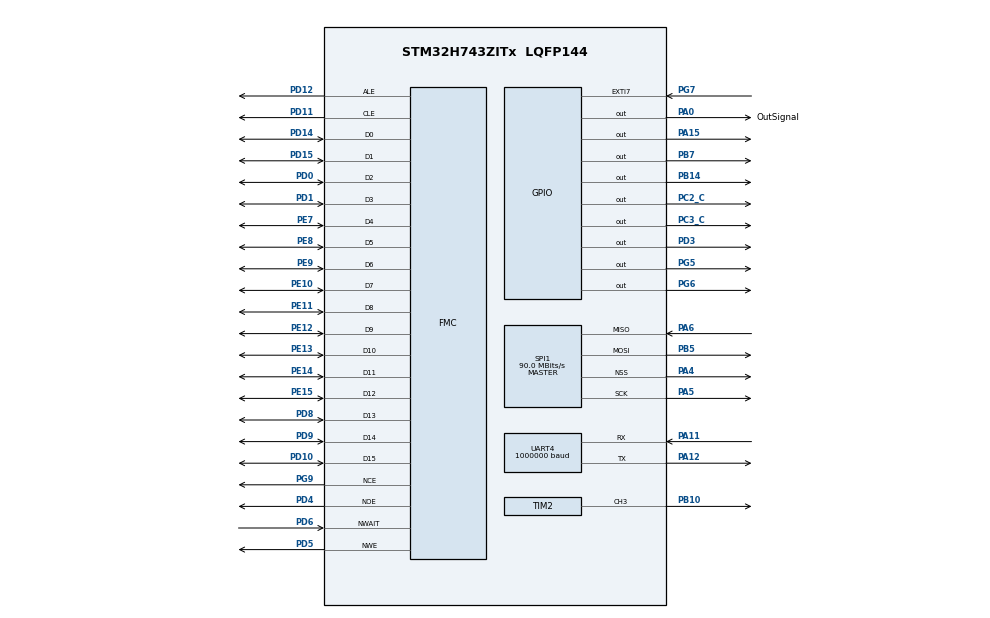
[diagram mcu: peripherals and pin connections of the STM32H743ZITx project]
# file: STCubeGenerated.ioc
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CORTEX_M7.AccessPermission-Cortex_Memory_Protection_Unit_Region0_Settings=MPU_REGION_FULL_ACCESS
CORTEX_M7.BaseAddress-Cortex_Memory_Protection_Unit_Region0_Settings=0x24060000
CORTEX_M7.CPU_DCache=Enabled
CORTEX_M7.CPU_ICache=Disabled
CORTEX_M7.Enable-Cortex_Memory_Protection_Unit_Region0_Settings=MPU_REGION_ENABLE
CORTEX_M7.IsBufferable-Cortex_Memory_Protection_Unit_Region0_Settings=MPU_ACCESS_BUFFERABLE
CORTEX_M7.IsShareable-Cortex_Memory_Protection_Unit_Region0_Settings=MPU_ACCESS_SHAREABLE
CORTEX_M7.MPU_Control=MPU_PRIVILEGED_DEFAULT
CORTEX_M7.Size-Cortex_Memory_Protection_Unit_Region0_Settings=MPU_REGION_SIZE_128KB
Dma.MEMTOMEM.0.Direction=DMA_MEMORY_TO_MEMORY
Dma.MEMTOMEM.0.EventEnable=DISABLE
Dma.MEMTOMEM.0.FIFOMode=DMA_FIFOMODE_ENABLE
Dma.MEMTOMEM.0.FIFOThreshold=DMA_FIFO_THRESHOLD_FULL
Dma.MEMTOMEM.0.Instance=DMA1_Stream0
Dma.MEMTOMEM.0.MemBurst=DMA_MBURST_SINGLE
Dma.MEMTOMEM.0.MemDataAlignment=DMA_MDATAALIGN_HALFWORD
Dma.MEMTOMEM.0.MemInc=DMA_MINC_ENABLE
Dma.MEMTOMEM.0.Mode=DMA_NORMAL
Dma.MEMTOMEM.0.PeriphBurst=DMA_PBURST_SINGLE
Dma.MEMTOMEM.0.PeriphDataAlignment=DMA_PDATAALIGN_HALFWORD
Dma.MEMTOMEM.0.PeriphInc=DMA_PINC_ENABLE
Dma.MEMTOMEM.0.Polarity=HAL_DMAMUX_REQ_GEN_RISING
Dma.MEMTOMEM.0.Priority=DMA_PRIORITY_VERY_HIGH
Dma.MEMTOMEM.0.RequestNumber=1
Dma.MEMTOMEM.0.SyncEnable=DISABLE
Dma.MEMTOMEM.0.SyncPolarity=HAL_DMAMUX_SYNC_NO_EVENT
Dma.MEMTOMEM.0.SyncRequestNumber=1
Dma.Request0=MEMTOMEM
Dma.Request1=UART4_RX
Dma.Request2=UART4_TX
Dma.Request3=SPI1_RX
Dma.Request4=SPI1_TX
Dma.SPI1_RX.3.Direction=DMA_PERIPH_TO_MEMORY
Dma.SPI1_RX.3.EventEnable=DISABLE
Dma.SPI1_RX.3.FIFOMode=DMA_FIFOMODE_ENABLE
Dma.SPI1_RX.3.FIFOThreshold=DMA_FIFO_THRESHOLD_HALFFULL
Dma.SPI1_RX.3.Instance=DMA1_Stream2
Dma.SPI1_RX.3.MemBurst=DMA_MBURST_SINGLE
Dma.SPI1_RX.3.MemDataAlignment=DMA_MDATAALIGN_HALFWORD
Dma.SPI1_RX.3.MemInc=DMA_MINC_ENABLE
Dma.SPI1_RX.3.Mode=DMA_NORMAL
Dma.SPI1_RX.3.PeriphBurst=DMA_PBURST_SINGLE
Dma.SPI1_RX.3.PeriphDataAlignment=DMA_PDATAALIGN_HALFWORD
Dma.SPI1_RX.3.PeriphInc=DMA_PINC_DISABLE
Dma.SPI1_RX.3.Polarity=HAL_DMAMUX_REQ_GEN_RISING
Dma.SPI1_RX.3.Priority=DMA_PRIORITY_MEDIUM
Dma.SPI1_RX.3.RequestNumber=1
Dma.SPI1_RX.3.SyncEnable=DISABLE
Dma.SPI1_RX.3.SyncPolarity=HAL_DMAMUX_SYNC_NO_EVENT
Dma.SPI1_RX.3.SyncRequestNumber=1
Dma.SPI1_TX.4.Direction=DMA_MEMORY_TO_PERIPH
Dma.SPI1_TX.4.EventEnable=DISABLE
Dma.SPI1_TX.4.FIFOMode=DMA_FIFOMODE_ENABLE
Dma.SPI1_TX.4.FIFOThreshold=DMA_FIFO_THRESHOLD_HALFFULL
Dma.SPI1_TX.4.Instance=DMA1_Stream3
Dma.SPI1_TX.4.MemBurst=DMA_MBURST_SINGLE
Dma.SPI1_TX.4.MemDataAlignment=DMA_MDATAALIGN_HALFWORD
Dma.SPI1_TX.4.MemInc=DMA_MINC_ENABLE
Dma.SPI1_TX.4.Mode=DMA_NORMAL
Dma.SPI1_TX.4.PeriphBurst=DMA_PBURST_SINGLE
Dma.SPI1_TX.4.PeriphDataAlignment=DMA_PDATAALIGN_HALFWORD
Dma.SPI1_TX.4.PeriphInc=DMA_PINC_DISABLE
Dma.SPI1_TX.4.Polarity=HAL_DMAMUX_REQ_GEN_RISING
Dma.SPI1_TX.4.Priority=DMA_PRIORITY_MEDIUM
Dma.SPI1_TX.4.RequestNumber=1
Dma.SPI1_TX.4.SyncEnable=DISABLE
Dma.SPI1_TX.4.SyncPolarity=HAL_DMAMUX_SYNC_NO_EVENT
Dma.SPI1_TX.4.SyncRequestNumber=1
Dma.UART4_RX.1.Direction=DMA_PERIPH_TO_MEMORY
Dma.UART4_RX.1.EventEnable=DISABLE
Dma.UART4_RX.1.FIFOMode=DMA_FIFOMODE_DISABLE
Dma.UART4_RX.1.Instance=DMA1_Stream5
Dma.UART4_RX.1.MemDataAlignment=DMA_MDATAALIGN_BYTE
Dma.UART4_RX.1.MemInc=DMA_MINC_ENABLE
Dma.UART4_RX.1.Mode=DMA_NORMAL
Dma.UART4_RX.1.PeriphDataAlignment=DMA_PDATAALIGN_BYTE
Dma.UART4_RX.1.PeriphInc=DMA_PINC_DISABLE
Dma.UART4_RX.1.Polarity=HAL_DMAMUX_REQ_GEN_RISING
Dma.UART4_RX.1.Priority=DMA_PRIORITY_MEDIUM
Dma.UART4_RX.1.RequestNumber=1
Dma.UART4_RX.1.SyncEnable=DISABLE
Dma.UART4_RX.1.SyncPolarity=HAL_DMAMUX_SYNC_NO_EVENT
Dma.UART4_RX.1.SyncRequestNumber=1
Dma.UART4_TX.2.Direction=DMA_MEMORY_TO_PERIPH
Dma.UART4_TX.2.EventEnable=DISABLE
Dma.UART4_TX.2.FIFOMode=DMA_FIFOMODE_DISABLE
Dma.UART4_TX.2.Instance=DMA1_Stream4
Dma.UART4_TX.2.MemDataAlignment=DMA_MDATAALIGN_BYTE
Dma.UART4_TX.2.MemInc=DMA_MINC_ENABLE
Dma.UART4_TX.2.Mode=DMA_NORMAL
Dma.UART4_TX.2.PeriphDataAlignment=DMA_PDATAALIGN_BYTE
Dma.UART4_TX.2.PeriphInc=DMA_PINC_DISABLE
Dma.UART4_TX.2.Polarity=HAL_DMAMUX_REQ_GEN_RISING
Dma.UART4_TX.2.Priority=DMA_PRIORITY_MEDIUM
Dma.UART4_TX.2.RequestNumber=1
Dma.UART4_TX.2.SyncEnable=DISABLE
Dma.UART4_TX.2.SyncPolarity=HAL_DMAMUX_SYNC_NO_EVENT
Dma.UART4_TX.2.SyncRequestNumber=1
FMC.CommonSpaceHiZSetupTime1=5
FMC.CommonSpaceHoldSetupTime1=5
FMC.CommonSpaceSetupTime1=5
FMC.CommonSpaceWaitSetupTime1=5
Mcu.Family=STM32H7
Mcu.Name=STM32H743ZITx
Mcu.Package=LQFP144
Mdma.MDMA_Channel0.Request0=SW
Mdma.MDMA_Channel0.RequestsNb=1
Mdma.MDMA_Channel0.SW.0.BlockCount=0
Mdma.MDMA_Channel0.SW.0.BlockDataLength=0
Mdma.MDMA_Channel0.SW.0.BufferTransferLength=16
Mdma.MDMA_Channel0.SW.0.CircularMode=MDMA_LINEAR_LIST
Mdma.MDMA_Channel0.SW.0.DataAlignment=MDMA_DATAALIGN_PACKENABLE
Mdma.MDMA_Channel0.SW.0.DestBlockAddressOffset=0
Mdma.MDMA_Channel0.SW.0.DestBurst=MDMA_DEST_BURST_SINGLE
Mdma.MDMA_Channel0.SW.0.DestDataSize=MDMA_DEST_DATASIZE_HALFWORD
Mdma.MDMA_Channel0.SW.0.DestinationInc=MDMA_DEST_INC_HALFWORD
Mdma.MDMA_Channel0.SW.0.DstAddress=0
Mdma.MDMA_Channel0.SW.0.Endianness=MDMA_LITTLE_ENDIANNESS_PRESERVE
Mdma.MDMA_Channel0.SW.0.Instance=MDMA_Channel0
Mdma.MDMA_Channel0.SW.0.MaskAddress=0
Mdma.MDMA_Channel0.SW.0.MaskData=0
Mdma.MDMA_Channel0.SW.0.Priority=MDMA_PRIORITY_VERY_HIGH
Mdma.MDMA_Channel0.SW.0.Rank=First
Mdma.MDMA_Channel0.SW.0.SourceBlockAddressOffset=-16
Mdma.MDMA_Channel0.SW.0.SourceBurst=MDMA_SOURCE_BURST_SINGLE
Mdma.MDMA_Channel0.SW.0.SourceDataSize=MDMA_SRC_DATASIZE_HALFWORD
Mdma.MDMA_Channel0.SW.0.SourceInc=MDMA_SRC_INC_HALFWORD
Mdma.MDMA_Channel0.SW.0.SrcAddress=0
Mdma.MDMA_Channel0.SW.0.TransferTriggerMode=MDMA_BLOCK_TRANSFER
Mdma.RequestSet0=MDMA_Channel0
Mdma.RequestSetsNb=1
NVIC.DMA1_Stream0_IRQn=true\:0\:0\:true\:false\:false\:true
NVIC.DMA1_Stream2_IRQn=true\:1\:0\:true\:false\:true\:false
NVIC.DMA1_Stream3_IRQn=true\:1\:0\:true\:false\:false\:false
NVIC.DMA1_Stream4_IRQn=true\:1\:0\:true\:false\:true\:false
NVIC.DMA1_Stream5_IRQn=true\:1\:0\:true\:false\:true\:true
NVIC.EXTI9_5_IRQn=true\:0\:0\:true\:false\:false\:true
NVIC.MDMA_IRQn=true\:0\:0\:false\:false\:false\:true
NVIC.PriorityGroup=NVIC_PRIORITYGROUP_4
NVIC.SPI1_IRQn=true\:1\:0\:true\:false\:true\:false
NVIC.TIM7_IRQn=true\:1\:0\:true\:false\:true\:false
NVIC.TimeBase=TIM7_IRQn
NVIC.TimeBaseIP=TIM7
NVIC.UART4_IRQn=true\:1\:0\:true\:false\:true\:true
PA0-WKUP.GPIO_Label=OutSignal
PA0-WKUP.GPIO_Speed=GPIO_SPEED_FREQ_VERY_HIGH
PA0-WKUP.Signal=GPIO_Output
PA11.GPIO_ModeDefaultPP=GPIO_MODE_AF_PP
PA11.GPIO_PuPd=GPIO_NOPULL
PA11.GPIO_Speed=GPIO_SPEED_FREQ_VERY_HIGH
PA11.Mode=Asynchronous
PA11.Signal=UART4_RX
PA12.GPIO_ModeDefaultPP=GPIO_MODE_AF_PP
PA12.GPIO_PuPd=GPIO_NOPULL
PA12.GPIO_Speed=GPIO_SPEED_FREQ_VERY_HIGH
PA12.Mode=Asynchronous
PA12.Signal=UART4_TX
PA13.Mode=Trace_Asynchronous_SW
PA13.Signal=SYS_JTMS-SWDIO
PA14.Mode=Trace_Asynchronous_SW
PA14.Signal=SYS_JTCK-SWCLK
PA15.GPIO_ModeDefaultOutputPP=GPIO_MODE_OUTPUT_PP
PA15.GPIO_PuPd=GPIO_NOPULL
PA15.GPIO_Speed=GPIO_SPEED_FREQ_LOW
PA15.PinState=GPIO_PIN_RESET
PA15.Signal=GPIO_Output
PA4.GPIO_PuPd=GPIO_PULLUP
PA4.GPIO_Speed=GPIO_SPEED_FREQ_VERY_HIGH
PA4.Mode=NSS_Signal_Hard_Output
PA4.Signal=SPI1_NSS
PA5.GPIO_Speed=GPIO_SPEED_FREQ_VERY_HIGH
PA5.Mode=Full_Duplex_Master
PA5.Signal=SPI1_SCK
PA6.GPIO_Speed=GPIO_SPEED_FREQ_VERY_HIGH
PA6.Mode=Full_Duplex_Master
PA6.Signal=SPI1_MISO
PB10.Signal=S_TIM2_CH3
PB14.GPIO_ModeDefaultOutputPP=GPIO_MODE_OUTPUT_PP
PB14.GPIO_PuPd=GPIO_NOPULL
PB14.GPIO_Speed=GPIO_SPEED_FREQ_LOW
PB14.PinState=GPIO_PIN_RESET
PB14.Signal=GPIO_Output
PB3.Mode=Trace_Asynchronous_SW
PB3.Signal=SYS_JTDO-SWO
PB5.GPIO_Speed=GPIO_SPEED_FREQ_VERY_HIGH
PB5.Mode=Full_Duplex_Master
PB5.Signal=SPI1_MOSI
PB7.GPIO_FM7=__NULL
PB7.GPIO_ModeDefaultOutputPP=GPIO_MODE_OUTPUT_PP
PB7.GPIO_PuPd=GPIO_NOPULL
PB7.GPIO_Speed=GPIO_SPEED_FREQ_LOW
PB7.PinState=GPIO_PIN_RESET
PB7.Signal=GPIO_Output
PC2_C.GPIO_ModeDefaultOutputPP=GPIO_MODE_OUTPUT_PP
PC2_C.GPIO_PuPd=GPIO_NOPULL
PC2_C.GPIO_Speed=GPIO_SPEED_FREQ_LOW
PC2_C.PinState=GPIO_PIN_RESET
PC2_C.Signal=GPIO_Output
PC3_C.GPIO_ModeDefaultOutputPP=GPIO_MODE_OUTPUT_PP
PC3_C.GPIO_PuPd=GPIO_NOPULL
PC3_C.GPIO_Speed=GPIO_SPEED_FREQ_LOW
PC3_C.PinState=GPIO_PIN_RESET
PC3_C.Signal=GPIO_Output
PD0.Signal=FMC_D2_DA2
PD1.Signal=FMC_D3_DA3
PD10.Signal=FMC_D15_DA15
PD11.Signal=FMC_A16_CLE
PD12.Signal=FMC_A17_ALE
PD14.Signal=FMC_D0_DA0
PD15.Signal=FMC_D1_DA1
PD3.GPIO_ModeDefaultOutputPP=GPIO_MODE_OUTPUT_PP
PD3.GPIO_PuPd=GPIO_NOPULL
PD3.GPIO_Speed=GPIO_SPEED_FREQ_LOW
PD3.PinState=GPIO_PIN_RESET
PD3.Signal=GPIO_Output
PD4.Signal=FMC_NOE
PD5.Signal=FMC_NWE
PD6.Signal=FMC_NWAIT
PD8.Signal=FMC_D13_DA13
PD9.Signal=FMC_D14_DA14
PE10.Signal=FMC_D7_DA7
PE11.Signal=FMC_D8_DA8
PE12.Signal=FMC_D9_DA9
PE13.Signal=FMC_D10_DA10
PE14.Signal=FMC_D11_DA11
PE15.Signal=FMC_D12_DA12
PE7.Signal=FMC_D4_DA4
PE8.Signal=FMC_D5_DA5
PE9.Signal=FMC_D6_DA6
PG5.GPIO_PuPd=GPIO_PULLUP
PG5.GPIO_Speed=GPIO_SPEED_FREQ_VERY_HIGH
PG5.Signal=GPIO_Output
PG6.GPIO_ModeDefaultOutputPP=GPIO_MODE_OUTPUT_PP
PG6.GPIO_PuPd=GPIO_PULLDOWN
PG6.GPIO_Speed=GPIO_SPEED_FREQ_VERY_HIGH
PG6.Signal=GPIO_Output
PG7.GPIO_ModeDefaultEXTI=GPIO_MODE_IT_RISING
PG7.GPIO_PuPd=GPIO_NOPULL
PG7.Signal=GPXTI7
PG9.Mode=NandChipSelect3_1
PG9.Signal=FMC_NCE
PH0-OSC_IN.Mode=HSE-External-Clock-Source
PH0-OSC_IN.Signal=RCC_OSC_IN
PH1-OSC_OUT.Mode=HSE-External-Clock-Source
PH1-OSC_OUT.Signal=RCC_OSC_OUT
ProjectManager.HeapSize=0x200
ProjectManager.StackSize=0x400
ProjectManager.TargetToolchain=Makefile
RCC.ADCFreq_Value=360000000
RCC.APB1Freq_Value=97500000
RCC.APB2Freq_Value=97500000
RCC.APB3Freq_Value=97500000
RCC.APB4Freq_Value=97500000
RCC.CortexFreq_Value=390000000
RCC.D1PPRE=RCC_APB3_DIV2
RCC.D2PPRE1=RCC_APB1_DIV2
RCC.D2PPRE2=RCC_APB2_DIV2
RCC.D3PPRE=RCC_APB4_DIV2
RCC.DIVM1=2
RCC.DIVM2=2
RCC.DIVN1=195
RCC.DIVN2=180
RCC.HCLKFreq_Value=195000000
RCC.HPRE=RCC_HCLK_DIV2
RCC.HSE_VALUE=8000000
RCC.PLLSourceVirtual=RCC_PLLSOURCE_HSE
RCC.SPI123CLockSelection=RCC_SPI123CLKSOURCE_PLL2
RCC.SYSCLKFreq_VALUE=390000000
RCC.SYSCLKSource=RCC_SYSCLKSOURCE_PLLCLK
RCC.USBFreq_Value=390000000
SH.FMC_A16_CLE.0=FMC_CLE,16b-dmux1
SH.FMC_A17_ALE.0=FMC_ALE,16b-dmux1
SH.FMC_D0_DA0.0=FMC_D0,16b-dmux1
SH.FMC_D10_DA10.0=FMC_D10,16b-dmux1
SH.FMC_D11_DA11.0=FMC_D11,16b-dmux1
SH.FMC_D12_DA12.0=FMC_D12,16b-dmux1
SH.FMC_D13_DA13.0=FMC_D13,16b-dmux1
SH.FMC_D14_DA14.0=FMC_D14,16b-dmux1
SH.FMC_D15_DA15.0=FMC_D15,16b-dmux1
SH.FMC_D1_DA1.0=FMC_D1,16b-dmux1
SH.FMC_D2_DA2.0=FMC_D2,16b-dmux1
SH.FMC_D3_DA3.0=FMC_D3,16b-dmux1
SH.FMC_D4_DA4.0=FMC_D4,16b-dmux1
SH.FMC_D5_DA5.0=FMC_D5,16b-dmux1
SH.FMC_D6_DA6.0=FMC_D6,16b-dmux1
SH.FMC_D7_DA7.0=FMC_D7,16b-dmux1
SH.FMC_D8_DA8.0=FMC_D8,16b-dmux1
SH.FMC_D9_DA9.0=FMC_D9,16b-dmux1
SH.FMC_NOE.0=FMC_NOE,16b-dmux1
SH.FMC_NWAIT.0=FMC_NWAIT,Wait1
SH.FMC_NWE.0=FMC_NWE,16b-dmux1
SH.S_TIM2_CH3.0=TIM2_CH3,PWM Generation3 CH3
SPI1.BaudRatePrescaler=SPI_BAUDRATEPRESCALER_4
SPI1.CalculateBaudRate=90.0 MBits/s
SPI1.DataSize=SPI_DATASIZE_16BIT
SPI1.Direction=SPI_DIRECTION_2LINES
SPI1.Mode=SPI_MODE_MASTER
SPI1.VirtualNSS=VM_NSSHARD
SPI1.VirtualType=VM_MASTER
TIM2.Channel-PWM\ Generation3\ CH3=TIM_CHANNEL_3
TIM2.Period=1079
TIM2.Pulse-PWM\ Generation3\ CH3=100
UART4.BaudRate=1000000
UART4.FIFOMode=FIFOMODE_ENABLE
UART4.WordLength=WORDLENGTH_8B
VP_SYS_VS_tim7.Mode=TIM7
board=STCubeGenerated

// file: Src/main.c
/**
  ******************************************************************************
  * @file           : main.c
  * @brief          : Main program body
  ******************************************************************************
  ** This notice applies to any and all portions of this file
  * that are not between comment pairs USER CODE BEGIN and
  * USER CODE END. Other portions of this file, whether
  * inserted by the user or by software development tools
  * are owned by their respective copyright owners.
  *
  * COPYRIGHT(c) 2018 STMicroelectronics
  *
  * Redistribution and use in source and binary forms, with or without modification,
  * are permitted provided that the following conditions are met:
  *   1. Redistributions of source code must retain the above copyright notice,
  *      this list of conditions and the following disclaimer.
  *   2. Redistributions in binary form must reproduce the above copyright notice,
  *      this list of conditions and the following disclaimer in the documentation
  *      and/or other materials provided with the distribution.
  *   3. Neither the name of STMicroelectronics nor the names of its contributors
  *      may be used to endorse or promote products derived from this software
  *      without specific prior written permission.
  *
  * THIS SOFTWARE IS PROVIDED BY THE COPYRIGHT HOLDERS AND CONTRIBUTORS "AS IS"
  * AND ANY EXPRESS OR IMPLIED WARRANTIES, INCLUDING, BUT NOT LIMITED TO, THE
  * IMPLIED WARRANTIES OF MERCHANTABILITY AND FITNESS FOR A PARTICULAR PURPOSE ARE
  * DISCLAIMED. IN NO EVENT SHALL THE COPYRIGHT HOLDER OR CONTRIBUTORS BE LIABLE
  * FOR ANY DIRECT, INDIRECT, INCIDENTAL, SPECIAL, EXEMPLARY, OR CONSEQUENTIAL
  * DAMAGES (INCLUDING, BUT NOT LIMITED TO, PROCUREMENT OF SUBSTITUTE GOODS OR
  * SERVICES; LOSS OF USE, DATA, OR PROFITS; OR BUSINESS INTERRUPTION) HOWEVER
  * CAUSED AND ON ANY THEORY OF LIABILITY, WHETHER IN CONTRACT, STRICT LIABILITY,
  * OR TORT (INCLUDING NEGLIGENCE OR OTHERWISE) ARISING IN ANY WAY OUT OF THE USE
  * OF THIS SOFTWARE, EVEN IF ADVISED OF THE POSSIBILITY OF SUCH DAMAGE.
  *
  ******************************************************************************
  */
#include "main.h"
#include "stm32h7xx_hal.h"

/* USER CODE BEGIN Includes */
#include "cmsis_os2.h"                  // ::CMSIS:RTOS2
/* USER CODE END Includes */

SPI_HandleTypeDef hspi1;
DMA_HandleTypeDef hdma_spi1_rx;
DMA_HandleTypeDef hdma_spi1_tx;

TIM_HandleTypeDef htim2;

UART_HandleTypeDef huart4;
DMA_HandleTypeDef hdma_uart4_rx;
DMA_HandleTypeDef hdma_uart4_tx;

DMA_HandleTypeDef hdma_memtomem_dma1_stream0;
MDMA_HandleTypeDef hmdma_mdma_channel0_sw_0;
NAND_HandleTypeDef hnand1;

/* USER CODE BEGIN PV */
/* Private variables ---------------------------------------------------------*/

/* USER CODE END PV */

void SystemClock_Config(void);
static void MPU_Config(void);
static void MX_GPIO_Init(void);
static void MX_DMA_Init(void);
static void MX_MDMA_Init(void);
static void MX_FMC_Init(void);
static void MX_TIM2_Init(void);
static void MX_UART4_Init(void);
static void MX_SPI1_Init(void);

void HAL_TIM_MspPostInit(TIM_HandleTypeDef *htim);

/* USER CODE BEGIN PFP */
/* Private function prototypes -----------------------------------------------*/

/* USER CODE END PFP */

/* USER CODE BEGIN 0 */
extern osThreadId_t tid_Thread;                                      // thread id
void Thread (void *argument);                                 // thread function
/* USER CODE END 0 */

int main(void)
{
  /* USER CODE BEGIN 1 */
	osThreadAttr_t worker_attr;
  /* USER CODE END 1 */

  /* MPU Configuration----------------------------------------------------------*/
  MPU_Config();

  /* Enable D-Cache-------------------------------------------------------------*/
  SCB_EnableDCache();

  /* MCU Configuration----------------------------------------------------------*/

  /* Reset of all peripherals, Initializes the Flash interface and the Systick. */
  HAL_Init();

  /* Configure the system clock */
  SystemClock_Config();

  /* USER CODE BEGIN SysInit */
  osKernelInitialize();
	memset(&worker_attr, 0, sizeof(worker_attr));
  worker_attr.stack_size = 2000;
	tid_Thread = osThreadNew (Thread, NULL, &worker_attr);
  /* USER CODE END SysInit */

  /* Initialize all configured peripherals */
  MX_GPIO_Init();
  MX_DMA_Init();
  MX_MDMA_Init();
  MX_FMC_Init();
  MX_TIM2_Init();
  MX_UART4_Init();
  MX_SPI1_Init();
  /* USER CODE BEGIN 2 */
  if (osKernelGetState() == osKernelReady)
  {
    osKernelStart();
  }
  /* USER CODE END 2 */

  /* Infinite loop */
  while (1)
  {

  }

}

void SystemClock_Config(void)
{

  RCC_OscInitTypeDef RCC_OscInitStruct;
  RCC_ClkInitTypeDef RCC_ClkInitStruct;
  RCC_PeriphCLKInitTypeDef PeriphClkInitStruct;

    /**Supply configuration update enable
    */
  MODIFY_REG(PWR->CR3, PWR_CR3_SCUEN, 0);

    /**Configure the main internal regulator output voltage
    */
  __HAL_PWR_VOLTAGESCALING_CONFIG(PWR_REGULATOR_VOLTAGE_SCALE1);

  while ((PWR->D3CR & (PWR_D3CR_VOSRDY)) != PWR_D3CR_VOSRDY)
  {

  }
    /**Macro to configure the PLL clock source
    */
  __HAL_RCC_PLL_PLLSOURCE_CONFIG(RCC_PLLSOURCE_HSE);

    /**Initializes the CPU, AHB and APB busses clocks
    */
  RCC_OscInitStruct.OscillatorType = RCC_OSCILLATORTYPE_HSE;
  RCC_OscInitStruct.HSEState = RCC_HSE_BYPASS;
  RCC_OscInitStruct.PLL.PLLState = RCC_PLL_ON;
  RCC_OscInitStruct.PLL.PLLSource = RCC_PLLSOURCE_HSE;
  RCC_OscInitStruct.PLL.PLLM = 2;
  RCC_OscInitStruct.PLL.PLLN = 195;
  RCC_OscInitStruct.PLL.PLLP = 2;
  RCC_OscInitStruct.PLL.PLLQ = 2;
  RCC_OscInitStruct.PLL.PLLR = 2;
  RCC_OscInitStruct.PLL.PLLRGE = RCC_PLL1VCIRANGE_2;
  RCC_OscInitStruct.PLL.PLLVCOSEL = RCC_PLL1VCOWIDE;
  RCC_OscInitStruct.PLL.PLLFRACN = 0;
  if (HAL_RCC_OscConfig(&RCC_OscInitStruct) != HAL_OK)
  {
    _Error_Handler(__FILE__, __LINE__);
  }

    /**Initializes the CPU, AHB and APB busses clocks
    */
  RCC_ClkInitStruct.ClockType = RCC_CLOCKTYPE_HCLK|RCC_CLOCKTYPE_SYSCLK
                              |RCC_CLOCKTYPE_PCLK1|RCC_CLOCKTYPE_PCLK2
                              |RCC_CLOCKTYPE_D3PCLK1|RCC_CLOCKTYPE_D1PCLK1;
  RCC_ClkInitStruct.SYSCLKSource = RCC_SYSCLKSOURCE_PLLCLK;
  RCC_ClkInitStruct.SYSCLKDivider = RCC_SYSCLK_DIV1;
  RCC_ClkInitStruct.AHBCLKDivider = RCC_HCLK_DIV2;
  RCC_ClkInitStruct.APB3CLKDivider = RCC_APB3_DIV2;
  RCC_ClkInitStruct.APB1CLKDivider = RCC_APB1_DIV2;
  RCC_ClkInitStruct.APB2CLKDivider = RCC_APB2_DIV2;
  RCC_ClkInitStruct.APB4CLKDivider = RCC_APB4_DIV2;

  if (HAL_RCC_ClockConfig(&RCC_ClkInitStruct, FLASH_LATENCY_2) != HAL_OK)
  {
    _Error_Handler(__FILE__, __LINE__);
  }

  PeriphClkInitStruct.PeriphClockSelection = RCC_PERIPHCLK_UART4|RCC_PERIPHCLK_SPI1
                              |RCC_PERIPHCLK_FMC;
  PeriphClkInitStruct.PLL2.PLL2M = 2;
  PeriphClkInitStruct.PLL2.PLL2N = 180;
  PeriphClkInitStruct.PLL2.PLL2P = 2;
  PeriphClkInitStruct.PLL2.PLL2Q = 2;
  PeriphClkInitStruct.PLL2.PLL2R = 2;
  PeriphClkInitStruct.PLL2.PLL2RGE = RCC_PLL2VCIRANGE_2;
  PeriphClkInitStruct.PLL2.PLL2VCOSEL = RCC_PLL2VCOWIDE;
  PeriphClkInitStruct.PLL2.PLL2FRACN = 0;
  PeriphClkInitStruct.FmcClockSelection = RCC_FMCCLKSOURCE_D1HCLK;
  PeriphClkInitStruct.Spi123ClockSelection = RCC_SPI123CLKSOURCE_PLL2;
  PeriphClkInitStruct.Usart234578ClockSelection = RCC_USART234578CLKSOURCE_D2PCLK1;
  if (HAL_RCCEx_PeriphCLKConfig(&PeriphClkInitStruct) != HAL_OK)
  {
    _Error_Handler(__FILE__, __LINE__);
  }

    /**Configure the Systick interrupt time
    */
  HAL_SYSTICK_Config(SystemCoreClock/1000);

    /**Configure the Systick
    */
  HAL_SYSTICK_CLKSourceConfig(SYSTICK_CLKSOURCE_HCLK);

  /* SysTick_IRQn interrupt configuration */
  HAL_NVIC_SetPriority(SysTick_IRQn, 15, 0);
}

/* SPI1 init function */
static void MX_SPI1_Init(void)
{

  /* SPI1 parameter configuration*/
  hspi1.Instance = SPI1;
  hspi1.Init.Mode = SPI_MODE_MASTER;
  hspi1.Init.Direction = SPI_DIRECTION_2LINES;
  hspi1.Init.DataSize = SPI_DATASIZE_16BIT;
  hspi1.Init.CLKPolarity = SPI_POLARITY_LOW;
  hspi1.Init.CLKPhase = SPI_PHASE_1EDGE;
  hspi1.Init.NSS = SPI_NSS_HARD_OUTPUT;
  hspi1.Init.BaudRatePrescaler = SPI_BAUDRATEPRESCALER_4;
  hspi1.Init.FirstBit = SPI_FIRSTBIT_MSB;
  hspi1.Init.TIMode = SPI_TIMODE_DISABLE;
  hspi1.Init.CRCCalculation = SPI_CRCCALCULATION_DISABLE;
  hspi1.Init.CRCPolynomial = 7;
  hspi1.Init.NSSPMode = SPI_NSS_PULSE_ENABLE;
  hspi1.Init.NSSPolarity = SPI_NSS_POLARITY_LOW;
  hspi1.Init.FifoThreshold = SPI_FIFO_THRESHOLD_01DATA;
  hspi1.Init.TxCRCInitializationPattern = SPI_CRC_INITIALIZATION_ALL_ZERO_PATTERN;
  hspi1.Init.RxCRCInitializationPattern = SPI_CRC_INITIALIZATION_ALL_ZERO_PATTERN;
  hspi1.Init.MasterSSIdleness = SPI_MASTER_SS_IDLENESS_00CYCLE;
  hspi1.Init.MasterInterDataIdleness = SPI_MASTER_INTERDATA_IDLENESS_00CYCLE;
  hspi1.Init.MasterReceiverAutoSusp = SPI_MASTER_INTERDATA_IDLENESS_00CYCLE;
  hspi1.Init.MasterKeepIOState = SPI_MASTER_KEEP_IO_STATE_DISABLE;
  hspi1.Init.IOSwap = SPI_IO_SWAP_DISABLE;
  if (HAL_SPI_Init(&hspi1) != HAL_OK)
  {
    _Error_Handler(__FILE__, __LINE__);
  }

}

/* TIM2 init function */
static void MX_TIM2_Init(void)
{

  TIM_MasterConfigTypeDef sMasterConfig;
  TIM_OC_InitTypeDef sConfigOC;

  htim2.Instance = TIM2;
  htim2.Init.Prescaler = 0;
  htim2.Init.CounterMode = TIM_COUNTERMODE_UP;
  htim2.Init.Period = 1079;
  htim2.Init.ClockDivision = TIM_CLOCKDIVISION_DIV1;
  htim2.Init.AutoReloadPreload = TIM_AUTORELOAD_PRELOAD_DISABLE;
  if (HAL_TIM_PWM_Init(&htim2) != HAL_OK)
  {
    _Error_Handler(__FILE__, __LINE__);
  }

  sMasterConfig.MasterOutputTrigger = TIM_TRGO_RESET;
  sMasterConfig.MasterSlaveMode = TIM_MASTERSLAVEMODE_DISABLE;
  if (HAL_TIMEx_MasterConfigSynchronization(&htim2, &sMasterConfig) != HAL_OK)
  {
    _Error_Handler(__FILE__, __LINE__);
  }

  sConfigOC.OCMode = TIM_OCMODE_PWM1;
  sConfigOC.Pulse = 100;
  sConfigOC.OCPolarity = TIM_OCPOLARITY_HIGH;
  sConfigOC.OCFastMode = TIM_OCFAST_DISABLE;
  if (HAL_TIM_PWM_ConfigChannel(&htim2, &sConfigOC, TIM_CHANNEL_3) != HAL_OK)
  {
    _Error_Handler(__FILE__, __LINE__);
  }

  HAL_TIM_MspPostInit(&htim2);

}

/* UART4 init function */
static void MX_UART4_Init(void)
{

  huart4.Instance = UART4;
  huart4.Init.BaudRate = 1000000;
  huart4.Init.WordLength = UART_WORDLENGTH_8B;
  huart4.Init.StopBits = UART_STOPBITS_1;
  huart4.Init.Parity = UART_PARITY_NONE;
  huart4.Init.Mode = UART_MODE_TX_RX;
  huart4.Init.HwFlowCtl = UART_HWCONTROL_NONE;
  huart4.Init.OverSampling = UART_OVERSAMPLING_16;
  huart4.Init.OneBitSampling = UART_ONE_BIT_SAMPLE_DISABLE;
  huart4.Init.Prescaler = UART_PRESCALER_DIV1;
  huart4.Init.FIFOMode = UART_FIFOMODE_ENABLE;
  huart4.Init.TXFIFOThreshold = UART_TXFIFO_THRESHOLD_1_8;
  huart4.Init.RXFIFOThreshold = UART_RXFIFO_THRESHOLD_1_8;
  huart4.AdvancedInit.AdvFeatureInit = UART_ADVFEATURE_NO_INIT;
  if (HAL_UART_Init(&huart4) != HAL_OK)
  {
    _Error_Handler(__FILE__, __LINE__);
  }

}

static void MX_DMA_Init(void)
{
  /* DMA controller clock enable */
  __HAL_RCC_DMA1_CLK_ENABLE();

  /* Configure DMA request hdma_memtomem_dma1_stream0 on DMA1_Stream0 */
  hdma_memtomem_dma1_stream0.Instance = DMA1_Stream0;
  hdma_memtomem_dma1_stream0.Init.Request = DMA_REQUEST_MEM2MEM;
  hdma_memtomem_dma1_stream0.Init.Direction = DMA_MEMORY_TO_MEMORY;
  hdma_memtomem_dma1_stream0.Init.PeriphInc = DMA_PINC_ENABLE;
  hdma_memtomem_dma1_stream0.Init.MemInc = DMA_MINC_ENABLE;
  hdma_memtomem_dma1_stream0.Init.PeriphDataAlignment = DMA_PDATAALIGN_HALFWORD;
  hdma_memtomem_dma1_stream0.Init.MemDataAlignment = DMA_MDATAALIGN_HALFWORD;
  hdma_memtomem_dma1_stream0.Init.Mode = DMA_NORMAL;
  hdma_memtomem_dma1_stream0.Init.Priority = DMA_PRIORITY_VERY_HIGH;
  hdma_memtomem_dma1_stream0.Init.FIFOMode = DMA_FIFOMODE_ENABLE;
  hdma_memtomem_dma1_stream0.Init.FIFOThreshold = DMA_FIFO_THRESHOLD_FULL;
  hdma_memtomem_dma1_stream0.Init.MemBurst = DMA_MBURST_SINGLE;
  hdma_memtomem_dma1_stream0.Init.PeriphBurst = DMA_PBURST_SINGLE;
  if (HAL_DMA_Init(&hdma_memtomem_dma1_stream0) != HAL_OK)
  {
    _Error_Handler(__FILE__, __LINE__);
  }

  /* DMA interrupt init */
  /* DMA1_Stream0_IRQn interrupt configuration */
  HAL_NVIC_SetPriority(DMA1_Stream0_IRQn, 0, 0);
  HAL_NVIC_EnableIRQ(DMA1_Stream0_IRQn);
  /* DMA1_Stream2_IRQn interrupt configuration */
  HAL_NVIC_SetPriority(DMA1_Stream2_IRQn, 1, 0);
  HAL_NVIC_EnableIRQ(DMA1_Stream2_IRQn);
  /* DMA1_Stream3_IRQn interrupt configuration */
  HAL_NVIC_SetPriority(DMA1_Stream3_IRQn, 1, 0);
  HAL_NVIC_EnableIRQ(DMA1_Stream3_IRQn);
  /* DMA1_Stream4_IRQn interrupt configuration */
  HAL_NVIC_SetPriority(DMA1_Stream4_IRQn, 1, 0);
  HAL_NVIC_EnableIRQ(DMA1_Stream4_IRQn);
  /* DMA1_Stream5_IRQn interrupt configuration */
  HAL_NVIC_SetPriority(DMA1_Stream5_IRQn, 1, 0);
  HAL_NVIC_EnableIRQ(DMA1_Stream5_IRQn);

}

/**
  * Enable MDMA controller clock
  * Configure MDMA for global transfers
  *   hmdma_mdma_channel0_sw_0
  */
static void MX_MDMA_Init(void)
{
  /* MDMA controller clock enable */
  __HAL_RCC_MDMA_CLK_ENABLE();
  /* Local variables */

  /* Configure MDMA channel MDMA_Channel0 */
  /* Configure MDMA request hmdma_mdma_channel0_sw_0 on MDMA_Channel0 */
  hmdma_mdma_channel0_sw_0.Instance = MDMA_Channel0;
  hmdma_mdma_channel0_sw_0.Init.Request = MDMA_REQUEST_SW;
  hmdma_mdma_channel0_sw_0.Init.TransferTriggerMode = MDMA_BLOCK_TRANSFER;
  hmdma_mdma_channel0_sw_0.Init.Priority = MDMA_PRIORITY_VERY_HIGH;
  hmdma_mdma_channel0_sw_0.Init.Endianness = MDMA_LITTLE_ENDIANNESS_PRESERVE;
  hmdma_mdma_channel0_sw_0.Init.SourceInc = MDMA_SRC_INC_HALFWORD;
  hmdma_mdma_channel0_sw_0.Init.DestinationInc = MDMA_DEST_INC_HALFWORD;
  hmdma_mdma_channel0_sw_0.Init.SourceDataSize = MDMA_SRC_DATASIZE_HALFWORD;
  hmdma_mdma_channel0_sw_0.Init.DestDataSize = MDMA_DEST_DATASIZE_HALFWORD;
  hmdma_mdma_channel0_sw_0.Init.DataAlignment = MDMA_DATAALIGN_PACKENABLE;
  hmdma_mdma_channel0_sw_0.Init.BufferTransferLength = 16;
  hmdma_mdma_channel0_sw_0.Init.SourceBurst = MDMA_SOURCE_BURST_SINGLE;
  hmdma_mdma_channel0_sw_0.Init.DestBurst = MDMA_DEST_BURST_SINGLE;
  hmdma_mdma_channel0_sw_0.Init.SourceBlockAddressOffset = -16;
  hmdma_mdma_channel0_sw_0.Init.DestBlockAddressOffset = 0;
  if (HAL_MDMA_Init(&hmdma_mdma_channel0_sw_0) != HAL_OK)
  {
    Error_Handler();
  }

  /* MDMA interrupt initialization */
  /* MDMA_IRQn interrupt configuration */
  HAL_NVIC_SetPriority(MDMA_IRQn, 0, 0);
  HAL_NVIC_EnableIRQ(MDMA_IRQn);

}
/* FMC initialization function */
static void MX_FMC_Init(void)
{
  FMC_NAND_PCC_TimingTypeDef ComSpaceTiming;
  FMC_NAND_PCC_TimingTypeDef AttSpaceTiming;

  /** Perform the NAND1 memory initialization sequence
  */
  hnand1.Instance = FMC_NAND_DEVICE;
  /* hnand1.Init */
  hnand1.Init.NandBank = FMC_NAND_BANK3;
  hnand1.Init.Waitfeature = FMC_NAND_WAIT_FEATURE_ENABLE;
  hnand1.Init.MemoryDataWidth = FMC_NAND_MEM_BUS_WIDTH_16;
  hnand1.Init.EccComputation = FMC_NAND_ECC_DISABLE;
  hnand1.Init.ECCPageSize = FMC_NAND_ECC_PAGE_SIZE_256BYTE;
  hnand1.Init.TCLRSetupTime = 0;
  hnand1.Init.TARSetupTime = 0;
  /* hnand1.Config */
  hnand1.Config.PageSize = 0;
  hnand1.Config.SpareAreaSize = 0;
  hnand1.Config.BlockSize = 0;
  hnand1.Config.BlockNbr = 0;
  hnand1.Config.PlaneNbr = 0;
  hnand1.Config.PlaneSize = 0;
  hnand1.Config.ExtraCommandEnable = DISABLE;
  /* ComSpaceTiming */
  ComSpaceTiming.SetupTime = 5;
  ComSpaceTiming.WaitSetupTime = 5;
  ComSpaceTiming.HoldSetupTime = 5;
  ComSpaceTiming.HiZSetupTime = 5;
  /* AttSpaceTiming */
  AttSpaceTiming.SetupTime = 252;
  AttSpaceTiming.WaitSetupTime = 252;
  AttSpaceTiming.HoldSetupTime = 252;
  AttSpaceTiming.HiZSetupTime = 252;

  if (HAL_NAND_Init(&hnand1, &ComSpaceTiming, &AttSpaceTiming) != HAL_OK)
  {
    _Error_Handler(__FILE__, __LINE__);
  }

}

/** Configure pins as
        * Analog
        * Input
        * Output
        * EVENT_OUT
        * EXTI
*/
static void MX_GPIO_Init(void)
{

  GPIO_InitTypeDef GPIO_InitStruct;

  /* GPIO Ports Clock Enable */
  __HAL_RCC_GPIOH_CLK_ENABLE();
  __HAL_RCC_GPIOC_CLK_ENABLE();
  __HAL_RCC_GPIOA_CLK_ENABLE();
  __HAL_RCC_GPIOE_CLK_ENABLE();
  __HAL_RCC_GPIOB_CLK_ENABLE();
  __HAL_RCC_GPIOD_CLK_ENABLE();
  __HAL_RCC_GPIOG_CLK_ENABLE();

  /*Configure GPIO pin Output Level */
  HAL_GPIO_WritePin(GPIOC, GPIO_PIN_2|GPIO_PIN_3, GPIO_PIN_RESET);

  /*Configure GPIO pin Output Level */
  HAL_GPIO_WritePin(GPIOA, OutSignal_Pin|GPIO_PIN_15, GPIO_PIN_RESET);

  /*Configure GPIO pin Output Level */
  HAL_GPIO_WritePin(GPIOB, GPIO_PIN_14|GPIO_PIN_7, GPIO_PIN_RESET);

  /*Configure GPIO pin Output Level */
  HAL_GPIO_WritePin(GPIOG, GPIO_PIN_5|GPIO_PIN_6, GPIO_PIN_RESET);

  /*Configure GPIO pin Output Level */
  HAL_GPIO_WritePin(GPIOD, GPIO_PIN_3, GPIO_PIN_RESET);

  /*Configure GPIO pins : PC2 PC3 */
  GPIO_InitStruct.Pin = GPIO_PIN_2|GPIO_PIN_3;
  GPIO_InitStruct.Mode = GPIO_MODE_OUTPUT_PP;
  GPIO_InitStruct.Pull = GPIO_NOPULL;
  GPIO_InitStruct.Speed = GPIO_SPEED_FREQ_LOW;
  HAL_GPIO_Init(GPIOC, &GPIO_InitStruct);

  /*Configure GPIO pin : OutSignal_Pin */
  GPIO_InitStruct.Pin = OutSignal_Pin;
  GPIO_InitStruct.Mode = GPIO_MODE_OUTPUT_PP;
  GPIO_InitStruct.Pull = GPIO_NOPULL;
  GPIO_InitStruct.Speed = GPIO_SPEED_FREQ_VERY_HIGH;
  HAL_GPIO_Init(OutSignal_GPIO_Port, &GPIO_InitStruct);

  /*Configure GPIO pins : PB14 PB7 */
  GPIO_InitStruct.Pin = GPIO_PIN_14|GPIO_PIN_7;
  GPIO_InitStruct.Mode = GPIO_MODE_OUTPUT_PP;
  GPIO_InitStruct.Pull = GPIO_NOPULL;
  GPIO_InitStruct.Speed = GPIO_SPEED_FREQ_LOW;
  HAL_GPIO_Init(GPIOB, &GPIO_InitStruct);

  /*Configure GPIO pin : PG5 */
  GPIO_InitStruct.Pin = GPIO_PIN_5;
  GPIO_InitStruct.Mode = GPIO_MODE_OUTPUT_PP;
  GPIO_InitStruct.Pull = GPIO_PULLUP;
  GPIO_InitStruct.Speed = GPIO_SPEED_FREQ_VERY_HIGH;
  HAL_GPIO_Init(GPIOG, &GPIO_InitStruct);

  /*Configure GPIO pin : PG6 */
  GPIO_InitStruct.Pin = GPIO_PIN_6;
  GPIO_InitStruct.Mode = GPIO_MODE_OUTPUT_PP;
  GPIO_InitStruct.Pull = GPIO_PULLDOWN;
  GPIO_InitStruct.Speed = GPIO_SPEED_FREQ_VERY_HIGH;
  HAL_GPIO_Init(GPIOG, &GPIO_InitStruct);

  /*Configure GPIO pin : PG7 */
  GPIO_InitStruct.Pin = GPIO_PIN_7;
  GPIO_InitStruct.Mode = GPIO_MODE_IT_RISING;
  GPIO_InitStruct.Pull = GPIO_NOPULL;
  HAL_GPIO_Init(GPIOG, &GPIO_InitStruct);

  /*Configure GPIO pin : PA15 */
  GPIO_InitStruct.Pin = GPIO_PIN_15;
  GPIO_InitStruct.Mode = GPIO_MODE_OUTPUT_PP;
  GPIO_InitStruct.Pull = GPIO_NOPULL;
  GPIO_InitStruct.Speed = GPIO_SPEED_FREQ_LOW;
  HAL_GPIO_Init(GPIOA, &GPIO_InitStruct);

  /*Configure GPIO pin : PD3 */
  GPIO_InitStruct.Pin = GPIO_PIN_3;
  GPIO_InitStruct.Mode = GPIO_MODE_OUTPUT_PP;
  GPIO_InitStruct.Pull = GPIO_NOPULL;
  GPIO_InitStruct.Speed = GPIO_SPEED_FREQ_LOW;
  HAL_GPIO_Init(GPIOD, &GPIO_InitStruct);

  /* EXTI interrupt init*/
  HAL_NVIC_SetPriority(EXTI9_5_IRQn, 0, 0);
  HAL_NVIC_EnableIRQ(EXTI9_5_IRQn);

}

/* MPU Configuration */

void MPU_Config(void)
{
  MPU_Region_InitTypeDef MPU_InitStruct;

  /* Disables the MPU */
  HAL_MPU_Disable();
    /**Initializes and configures the Region and the memory to be protected
    */
  MPU_InitStruct.Enable = MPU_REGION_ENABLE;
  MPU_InitStruct.Number = MPU_REGION_NUMBER0;
  MPU_InitStruct.BaseAddress = 0x24060000;
  MPU_InitStruct.Size = MPU_REGION_SIZE_128KB;
  MPU_InitStruct.SubRegionDisable = 0x0;
  MPU_InitStruct.TypeExtField = MPU_TEX_LEVEL0;
  MPU_InitStruct.AccessPermission = MPU_REGION_FULL_ACCESS;
  MPU_InitStruct.DisableExec = MPU_INSTRUCTION_ACCESS_ENABLE;
  MPU_InitStruct.IsShareable = MPU_ACCESS_SHAREABLE;
  MPU_InitStruct.IsCacheable = MPU_ACCESS_NOT_CACHEABLE;
  MPU_InitStruct.IsBufferable = MPU_ACCESS_BUFFERABLE;

  HAL_MPU_ConfigRegion(&MPU_InitStruct);

  /* Enables the MPU */
  HAL_MPU_Enable(MPU_PRIVILEGED_DEFAULT);

}
void HAL_TIM_PeriodElapsedCallback(TIM_HandleTypeDef *htim)
{
  if (htim->Instance == TIM7) {
    HAL_IncTick();
  }
}

void _Error_Handler(char *file, int line)
{
  while(1)
  {
  }
}

/************************ (C) COPYRIGHT STMicroelectronics *****END OF FILE****/
